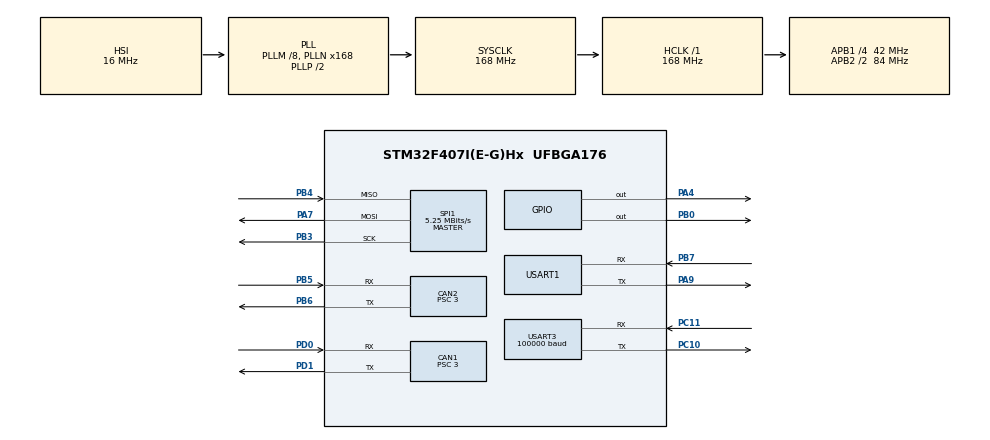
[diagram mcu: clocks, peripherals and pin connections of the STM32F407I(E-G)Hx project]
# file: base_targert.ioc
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CAN1.ABOM=ENABLE
CAN1.BS1=CAN_BS1_10TQ
CAN1.BS2=CAN_BS2_3TQ
CAN1.CalculateBaudRate=1000000
CAN1.CalculateTimeBit=1000
CAN1.CalculateTimeQuantum=71.42857142857143
CAN1.NART=ENABLE
CAN1.Prescaler=3
CAN2.ABOM=ENABLE
CAN2.BS1=CAN_BS1_10TQ
CAN2.BS2=CAN_BS2_3TQ
CAN2.CalculateBaudRate=1000000
CAN2.CalculateTimeBit=1000
CAN2.CalculateTimeQuantum=71.42857142857143
CAN2.NART=ENABLE
CAN2.Prescaler=3
Dma.Request0=USART3_RX
Dma.Request1=USART1_RX
Dma.Request2=USART1_TX
Dma.USART1_RX.1.Direction=DMA_PERIPH_TO_MEMORY
Dma.USART1_RX.1.FIFOMode=DMA_FIFOMODE_DISABLE
Dma.USART1_RX.1.Instance=DMA2_Stream2
Dma.USART1_RX.1.MemDataAlignment=DMA_MDATAALIGN_BYTE
Dma.USART1_RX.1.MemInc=DMA_MINC_ENABLE
Dma.USART1_RX.1.Mode=DMA_NORMAL
Dma.USART1_RX.1.PeriphDataAlignment=DMA_PDATAALIGN_BYTE
Dma.USART1_RX.1.PeriphInc=DMA_PINC_DISABLE
Dma.USART1_RX.1.Priority=DMA_PRIORITY_HIGH
Dma.USART1_TX.2.Direction=DMA_MEMORY_TO_PERIPH
Dma.USART1_TX.2.FIFOMode=DMA_FIFOMODE_DISABLE
Dma.USART1_TX.2.Instance=DMA2_Stream7
Dma.USART1_TX.2.MemDataAlignment=DMA_MDATAALIGN_BYTE
Dma.USART1_TX.2.MemInc=DMA_MINC_ENABLE
Dma.USART1_TX.2.Mode=DMA_CIRCULAR
Dma.USART1_TX.2.PeriphDataAlignment=DMA_PDATAALIGN_BYTE
Dma.USART1_TX.2.PeriphInc=DMA_PINC_DISABLE
Dma.USART1_TX.2.Priority=DMA_PRIORITY_HIGH
Dma.USART3_RX.0.Direction=DMA_PERIPH_TO_MEMORY
Dma.USART3_RX.0.FIFOMode=DMA_FIFOMODE_DISABLE
Dma.USART3_RX.0.Instance=DMA1_Stream1
Dma.USART3_RX.0.MemDataAlignment=DMA_MDATAALIGN_BYTE
Dma.USART3_RX.0.MemInc=DMA_MINC_ENABLE
Dma.USART3_RX.0.Mode=DMA_CIRCULAR
Dma.USART3_RX.0.PeriphDataAlignment=DMA_PDATAALIGN_BYTE
Dma.USART3_RX.0.PeriphInc=DMA_PINC_DISABLE
Dma.USART3_RX.0.Priority=DMA_PRIORITY_HIGH
FREERTOS.Tasks01=defaultTask,24,128,StartDefaultTask,Default,NULL,Dynamic,NULL,NULL;RcTask,32,256,OS_RcCallback,As weak,NULL,Dynamic,NULL,NULL;MotorTask,24,512,OS_MotorCallback,As weak,NULL,Dynamic,NULL,NULL;RamdomTask,24,1024,OS_RamdomCallback,As weak,NULL,Dynamic,NULL,NULL;JudgeTask,24,1024,OS_JudgeCallback,As weak,NULL,Dynamic,NULL,NULL;ErrorTask,48,128,OS_ErrorCallback,As weak,NULL,Dynamic,NULL,NULL
FREERTOS.configTOTAL_HEAP_SIZE=65536
Mcu.Family=STM32F4
Mcu.Name=STM32F407I(E-G)Hx
Mcu.Package=UFBGA176
NVIC.CAN1_RX0_IRQn=true\:5\:0\:false\:false\:true\:true\:true\:true\:true
NVIC.CAN2_RX0_IRQn=true\:5\:0\:false\:false\:true\:true\:true\:true\:true
NVIC.DMA1_Stream1_IRQn=true\:5\:0\:false\:false\:true\:true\:false\:true\:true
NVIC.DMA2_Stream2_IRQn=true\:5\:0\:false\:false\:true\:true\:false\:true\:true
NVIC.DMA2_Stream7_IRQn=true\:5\:0\:false\:false\:true\:true\:false\:true\:true
NVIC.PriorityGroup=NVIC_PRIORITYGROUP_4
NVIC.TIM2_IRQn=true\:15\:0\:false\:false\:true\:false\:false\:true\:true
NVIC.TIM6_DAC_IRQn=true\:5\:0\:false\:false\:true\:true\:true\:true\:true
NVIC.TimeBase=TIM2_IRQn
NVIC.TimeBaseIP=TIM2
NVIC.USART1_IRQn=true\:5\:0\:false\:false\:true\:true\:true\:true\:true
NVIC.USART3_IRQn=true\:5\:0\:false\:false\:true\:true\:true\:true\:true
PA13.Mode=Serial_Wire
PA13.Signal=SYS_JTMS-SWDIO
PA14.Mode=Serial_Wire
PA14.Signal=SYS_JTCK-SWCLK
PA4.GPIO_ModeDefaultOutputPP=GPIO_MODE_OUTPUT_PP
PA4.PinState=GPIO_PIN_SET
PA4.Signal=GPIO_Output
PA7.Mode=Full_Duplex_Master
PA7.Signal=SPI1_MOSI
PA9.Mode=Asynchronous
PA9.Signal=USART1_TX
PB0.PinState=GPIO_PIN_SET
PB0.Signal=GPIO_Output
PB3.Mode=Full_Duplex_Master
PB3.Signal=SPI1_SCK
PB4.Mode=Full_Duplex_Master
PB4.Signal=SPI1_MISO
PB5.Mode=CAN_Activate
PB5.Signal=CAN2_RX
PB6.Mode=CAN_Activate
PB6.Signal=CAN2_TX
PB7.Mode=Asynchronous
PB7.Signal=USART1_RX
PC10.Mode=Asynchronous
PC10.Signal=USART3_TX
PC11.Mode=Asynchronous
PC11.Signal=USART3_RX
PD0.Mode=CAN_Activate
PD0.Signal=CAN1_RX
PD1.Mode=CAN_Activate
PD1.Signal=CAN1_TX
PH0-OSC_IN.Mode=HSE-External-Oscillator
PH0-OSC_IN.Signal=RCC_OSC_IN
PH1-OSC_OUT.Mode=HSE-External-Oscillator
PH1-OSC_OUT.Signal=RCC_OSC_OUT
ProjectManager.HeapSize=0x3000
ProjectManager.StackSize=0x3000
ProjectManager.TargetToolchain=CMake
RCC.48MHZClocksFreq_Value=84000000
RCC.AHBFreq_Value=168000000
RCC.APB1CLKDivider=RCC_HCLK_DIV4
RCC.APB1Freq_Value=42000000
RCC.APB1TimFreq_Value=84000000
RCC.APB2CLKDivider=RCC_HCLK_DIV2
RCC.APB2Freq_Value=84000000
RCC.APB2TimFreq_Value=168000000
RCC.CortexFreq_Value=168000000
RCC.HCLKFreq_Value=168000000
RCC.HSE_VALUE=25000000
RCC.HSI_VALUE=16000000
RCC.LSE_VALUE=32768
RCC.PLLM=8
RCC.PLLN=168
RCC.SYSCLKFreq_VALUE=168000000
RCC.SYSCLKSource=RCC_SYSCLKSOURCE_PLLCLK
RCC.VCOOutputFreq_Value=336000000
SPI1.BaudRatePrescaler=SPI_BAUDRATEPRESCALER_16
SPI1.CLKPhase=SPI_PHASE_2EDGE
SPI1.CLKPolarity=SPI_POLARITY_HIGH
SPI1.CalculateBaudRate=5.25 MBits/s
SPI1.Direction=SPI_DIRECTION_2LINES
SPI1.Mode=SPI_MODE_MASTER
SPI1.VirtualType=VM_MASTER
TIM6.AutoReloadPreload=TIM_AUTORELOAD_PRELOAD_ENABLE
TIM6.Period=999
TIM6.Prescaler=83
USART1.VirtualMode=VM_ASYNC
USART3.BaudRate=100000
USART3.VirtualMode=VM_ASYNC
VP_FREERTOS_VS_CMSIS_V2.Mode=CMSIS_V2
VP_SYS_VS_tim2.Mode=TIM2
VP_TIM6_VS_ClockSourceINT.Mode=Enable_Timer
board=custom

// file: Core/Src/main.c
/* USER CODE BEGIN Header */
/**
  ******************************************************************************
  * @file           : main.c
  * @brief          : Main program body
  ******************************************************************************
  * @attention
  *
  * Copyright (c) 2026 STMicroelectronics.
  * All rights reserved.
  *
  * This software is licensed under terms that can be found in the LICENSE file
  * in the root directory of this software component.
  * If no LICENSE file comes with this software, it is provided AS-IS.
  *
  ******************************************************************************
  */
/* USER CODE END Header */
#include "main.h"
#include "cmsis_os.h"
#include "can.h"
#include "dma.h"
#include "spi.h"
#include "tim.h"
#include "usart.h"
#include "gpio.h"

/* USER CODE BEGIN Includes */

#include "Crc.h"
#include "pid.h"
#include "random.h"
#include "Judge.h"
#include "Motor.h"
#include "bsp_can.h"
#include "rc.h"

/* USER CODE END Includes */

void SystemClock_Config(void);
void MX_FREERTOS_Init(void);

int main(void)
{

  /* MCU Configuration--------------------------------------------------------*/

  /* Reset of all peripherals, Initializes the Flash interface and the Systick. */
  HAL_Init();

  /* Configure the system clock */
  SystemClock_Config();

  /* Initialize all configured peripherals */
  MX_GPIO_Init();
  MX_DMA_Init();
  MX_CAN1_Init();
  MX_CAN2_Init();
  MX_SPI1_Init();
  MX_USART3_UART_Init();
  MX_TIM6_Init();
  MX_USART1_UART_Init();
  /* USER CODE BEGIN 2 */

  can_user_init(&hcan1);
  JUDGE_Init();
  DBUS_Uart_Init(&huart3);

  /* USER CODE END 2 */

  /* Init scheduler */
  osKernelInitialize();  /* Call init function for freertos objects (in cmsis_os2.c) */
  MX_FREERTOS_Init();

  /* Start scheduler */
  osKernelStart();

  /* We should never get here as control is now taken by the scheduler */

  /* Infinite loop */
  while (1)
  {

  }
}

void SystemClock_Config(void)
{
  RCC_OscInitTypeDef RCC_OscInitStruct = {0};
  RCC_ClkInitTypeDef RCC_ClkInitStruct = {0};

  /** Configure the main internal regulator output voltage
  */
  __HAL_RCC_PWR_CLK_ENABLE();
  __HAL_PWR_VOLTAGESCALING_CONFIG(PWR_REGULATOR_VOLTAGE_SCALE1);

  /** Initializes the RCC Oscillators according to the specified parameters
  * in the RCC_OscInitTypeDef structure.
  */
  RCC_OscInitStruct.OscillatorType = RCC_OSCILLATORTYPE_HSI;
  RCC_OscInitStruct.HSIState = RCC_HSI_ON;
  RCC_OscInitStruct.HSICalibrationValue = RCC_HSICALIBRATION_DEFAULT;
  RCC_OscInitStruct.PLL.PLLState = RCC_PLL_ON;
  RCC_OscInitStruct.PLL.PLLSource = RCC_PLLSOURCE_HSI;
  RCC_OscInitStruct.PLL.PLLM = 8;
  RCC_OscInitStruct.PLL.PLLN = 168;
  RCC_OscInitStruct.PLL.PLLP = RCC_PLLP_DIV2;
  RCC_OscInitStruct.PLL.PLLQ = 4;
  if (HAL_RCC_OscConfig(&RCC_OscInitStruct) != HAL_OK)
  {
    Error_Handler();
  }

  /** Initializes the CPU, AHB and APB buses clocks
  */
  RCC_ClkInitStruct.ClockType = RCC_CLOCKTYPE_HCLK|RCC_CLOCKTYPE_SYSCLK
                              |RCC_CLOCKTYPE_PCLK1|RCC_CLOCKTYPE_PCLK2;
  RCC_ClkInitStruct.SYSCLKSource = RCC_SYSCLKSOURCE_PLLCLK;
  RCC_ClkInitStruct.AHBCLKDivider = RCC_SYSCLK_DIV1;
  RCC_ClkInitStruct.APB1CLKDivider = RCC_HCLK_DIV4;
  RCC_ClkInitStruct.APB2CLKDivider = RCC_HCLK_DIV2;

  if (HAL_RCC_ClockConfig(&RCC_ClkInitStruct, FLASH_LATENCY_5) != HAL_OK)
  {
    Error_Handler();
  }
}

void HAL_TIM_PeriodElapsedCallback(TIM_HandleTypeDef *htim)
{
  if (htim->Instance == TIM2)
  {
    HAL_IncTick();
  }
}

void Error_Handler(void)
{
  __disable_irq();
  while (1)
  {
  }
}

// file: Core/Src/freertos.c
/* USER CODE BEGIN Header */
/**
  ******************************************************************************
  * File Name          : freertos.c
  * Description        : Code for freertos applications
  ******************************************************************************
  * @attention
  *
  * Copyright (c) 2026 STMicroelectronics.
  * All rights reserved.
  *
  * This software is licensed under terms that can be found in the LICENSE file
  * in the root directory of this software component.
  * If no LICENSE file comes with this software, it is provided AS-IS.
  *
  ******************************************************************************
  */
/* USER CODE END Header */

#include "FreeRTOS.h"
#include "task.h"
#include "main.h"
#include "cmsis_os.h"

/* Definitions for defaultTask */
osThreadId_t defaultTaskHandle;
const osThreadAttr_t defaultTask_attributes = {
  .name = "defaultTask",
  .stack_size = 128 * 4,
  .priority = (osPriority_t) osPriorityNormal,
};
/* Definitions for RcTask */
osThreadId_t RcTaskHandle;
const osThreadAttr_t RcTask_attributes = {
  .name = "RcTask",
  .stack_size = 256 * 4,
  .priority = (osPriority_t) osPriorityAboveNormal,
};
/* Definitions for MotorTask */
osThreadId_t MotorTaskHandle;
const osThreadAttr_t MotorTask_attributes = {
  .name = "MotorTask",
  .stack_size = 512 * 4,
  .priority = (osPriority_t) osPriorityNormal,
};
/* Definitions for RamdomTask */
osThreadId_t RamdomTaskHandle;
const osThreadAttr_t RamdomTask_attributes = {
  .name = "RamdomTask",
  .stack_size = 1024 * 4,
  .priority = (osPriority_t) osPriorityNormal,
};
/* Definitions for JudgeTask */
osThreadId_t JudgeTaskHandle;
const osThreadAttr_t JudgeTask_attributes = {
  .name = "JudgeTask",
  .stack_size = 1024 * 4,
  .priority = (osPriority_t) osPriorityNormal,
};
/* Definitions for ErrorTask */
osThreadId_t ErrorTaskHandle;
const osThreadAttr_t ErrorTask_attributes = {
  .name = "ErrorTask",
  .stack_size = 128 * 4,
  .priority = (osPriority_t) osPriorityRealtime,
};

void StartDefaultTask(void *argument);
void OS_RcCallback(void *argument);
void OS_MotorCallback(void *argument);
void OS_RamdomCallback(void *argument);
void OS_JudgeCallback(void *argument);
void OS_ErrorCallback(void *argument);

void MX_FREERTOS_Init(void); /* (MISRA C 2004 rule 8.1) */

void MX_FREERTOS_Init(void) {

  /* Create the thread(s) */
  /* creation of defaultTask */
  defaultTaskHandle = osThreadNew(StartDefaultTask, NULL, &defaultTask_attributes);

  /* creation of RcTask */
  RcTaskHandle = osThreadNew(OS_RcCallback, NULL, &RcTask_attributes);

  /* creation of MotorTask */
  MotorTaskHandle = osThreadNew(OS_MotorCallback, NULL, &MotorTask_attributes);

  /* creation of RamdomTask */
  RamdomTaskHandle = osThreadNew(OS_RamdomCallback, NULL, &RamdomTask_attributes);

  /* creation of JudgeTask */
  JudgeTaskHandle = osThreadNew(OS_JudgeCallback, NULL, &JudgeTask_attributes);

  /* creation of ErrorTask */
  ErrorTaskHandle = osThreadNew(OS_ErrorCallback, NULL, &ErrorTask_attributes);

}

void StartDefaultTask(void *argument)
{
  for(;;)
  {
    osDelay(1);
  }
}

__weak void OS_RcCallback(void *argument)
{
  for(;;)
  {
    osDelay(1);
  }
}

__weak void OS_MotorCallback(void *argument)
{
  for(;;)
  {
    osDelay(1);
  }
}

__weak void OS_RamdomCallback(void *argument)
{
  for(;;)
  {
    osDelay(1);
  }
}

__weak void OS_JudgeCallback(void *argument)
{
  for(;;)
  {
    osDelay(1);
  }
}

__weak void OS_ErrorCallback(void *argument)
{
  for(;;)
  {
    osDelay(1);
  }
}
